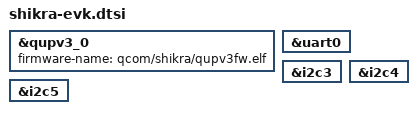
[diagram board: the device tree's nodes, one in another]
// SPDX-License-Identifier: BSD-3-Clause
/*
 * Copyright (c) Qualcomm Technologies, Inc. and/or its subsidiaries.
 */

&qupv3_0 {
	firmware-name = "qcom/shikra/qupv3fw.elf";

	status = "okay";
};

&uart0 {
	status = "okay";
};

&i2c3 {
    status = "okay";
};

&i2c4 {
    status = "okay";
};

&i2c5 {
    status = "okay";
};
